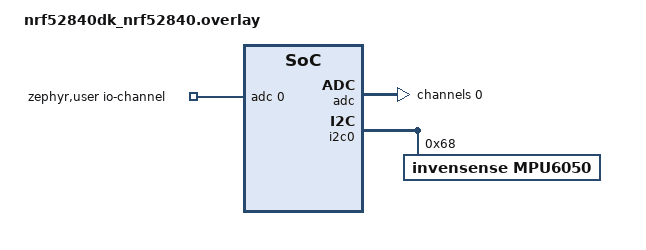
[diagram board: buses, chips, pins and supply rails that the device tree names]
/ {
	zephyr,user {
		io-channels = <&adc 0>;
	};
};

&adc {
	status = "okay";
	#address-cells = <1>;
	#size-cells = <0>;

	channel@0 {
		reg = <0>;
		zephyr,gain = "ADC_GAIN_1_6";
		zephyr,reference = "ADC_REF_INTERNAL";
		zephyr,acquisition-time = <ADC_ACQ_TIME_DEFAULT>;
		zephyr,input-positive = <NRF_SAADC_AIN1>; /* Pin A0 (P0.03) */
		zephyr,resolution = <12>;
	};
};

&i2c0 {
	status = "okay";
	pinctrl-0 = <&i2c0_default>;
	pinctrl-1 = <&i2c0_sleep>;
	pinctrl-names = "default", "sleep";

	mpu6050: mpu6050@68 {
		compatible = "invensense,mpu6050";
		reg = <0x68>;
		status = "okay";
	};
};
